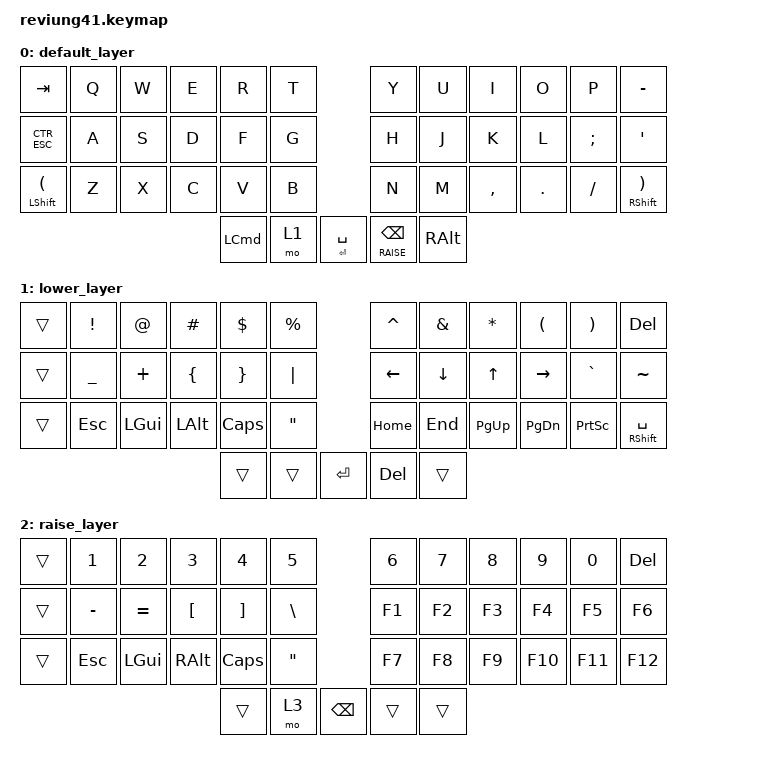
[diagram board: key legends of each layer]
/*
 * Copyright (c 2020 The ZMK Contributors
 *
 * SPDX-License-Identifier: MIT
 */

#include <behaviors.dtsi>
#include <dt-bindings/zmk/keys.h>
#include <dt-bindings/zmk/bt.h>

#define QWERTY 0
#define LOWER 1
#define RAISE 2

#define AS(keycode) &as LS(keycode) keycode

#define CTR_ESC &mt &mt LCTRL ESC
#define L_SHFT_PAR &mt LSHFT LPAR
#define R_SHFT_PAR &mt RSHFT RPAR
#define RET_SPC &mt RET SPACE
#define RS_BSPC &lt RAISE BSPC

&mt {
	tapping_term_ms = <150>;
};

/ {
        behaviors {
		as: auto_shift {
			compatible = "zmk,behavior-hold-tap";
			label = "AUTO_SHIFT";
			#binding-cells = <2>;
			tapping_term_ms = <175>;
			quick_tap_ms = <0>;
			flavor = "tap-preferred";
			bindings = <&kp>, <&kp>;
		};
	};

        keymap {
                compatible = "zmk,keymap";

                default_layer {
// -------------------------------------------------------------------------------------
// |  TAB |  Q  |  W  |  E  |  R  |  T  |   |  Y  |  U   |  I  |  O  |  P  |   -       |
// | CTRL |  A  |  S  |  D  |  F  |  G  |   |  H  |  J   |  K  |  L  |  ;  |    '      |
// | SHFT |  Z  |  X  |  C  |  V  |  B  |   |  N  |  M   |  ,  |  .  |  /  | SHFT(RET |
//                         | ALT | LWR | SPC | RSE  | ALT |
                        bindings = <
  &kp TAB    &kp Q &kp W &kp E &kp R     &kp T             &kp Y    &kp U  &kp I     &kp O   &kp P    &kp MINUS
  CTR_ESC    &kp A &kp S &kp D &kp F     &kp G             &kp H    &kp J  &kp K     &kp L   &kp SEMI &kp SQT
  L_SHFT_PAR &kp Z &kp X &kp C &kp V     &kp B             &kp N    &kp M  &kp COMMA &kp DOT &kp FSLH R_SHFT_PAR
                               &kp LCMD  &mo 1   RET_SPC   RS_BSPC  &kp RALT
                        >;
                };

                lower_layer {
// ------------------------------------------------------------------------------------
// |    |  !  |  @  |  #  |  $  |  %  |   |  ^  |  &  |  *  |  (  |    |      DEL    |
// |    |  _  |  +  |  {  |  }  | "|" |   | LFT | DWN |  UP | RGT |  `  |       ~     |
// |    | ESC | GUI | ALT | CAPS|  "  |   | HOME| END | PGUP| PGDN| PRSC| SHFT(SPACE |
//                       |     |     | RET | ADJ |     |
                        bindings = <
   &trans &kp EXCL  &kp AT      &kp HASH &kp DLLR &kp PRCNT      &kp CARET &kp AMPS &kp ASTRK &kp LPAR  &kp RPAR  &kp DEL
   &trans &kp UNDER &kp PLUS    &kp LBRC &kp RBRC &kp PIPE       &kp LEFT  &kp DOWN &kp UP    &kp RIGHT &kp GRAVE &kp TILDE
   &trans &kp ESC   &kp LGUI    &kp LALT &kp CLCK &kp DQT        &kp HOME  &kp END  &kp PG_UP &kp PG_DN &kp PSCRN &mt RSHFT SPACE
                                 &trans      &trans       &kp RET        &kp DEL       &trans
                        >;
                };

                raise_layer {
// ----------------------------------------------------------------------------
// |    |  1  |  2  |  3  |  4  |  5  |   |  6  |  7  |  8  |  9  |  0  | DEL |
// |    |  -  |  =  |  [  |  ]  |  \  |   | F1  | F2  | F3  | F4  | F5  | F6  |
// |    | ESC | GUI | ALT | CAPS|  "  |   | F7  | F8  | F9  | F10 | F11 | F12 |
//                       |     | ADJ | BKSP |    |     |
                        bindings = <
   &trans &kp N1    &kp N2    &kp N3    &kp N4    &kp N5        &kp N6    &kp N7    &kp N8    &kp N9    &kp N0    &kp DEL
   &trans &kp MINUS &kp EQUAL &kp LBKT  &kp RBKT  &kp BSLH      &kp F1    &kp F2    &kp F3    &kp F4    &kp F5    &kp F6
   &trans &kp ESC   &kp LGUI  &kp RALT  &kp CLCK  &kp DQT       &kp F7    &kp F8    &kp F9    &kp F10   &kp F11   &kp F12
                                &trans      &mo 3       &kp BSPC        &trans      &trans
                        >;
                };
        };
};
